# NUC1263AE register map
File version: 1.0
Registers are 32-bit, read-write, reset 0x0 unless marked. A register's access mark holds for its fields unless they carry their own. Offsets are from the block's base; [hi:lo] are bit positions; {n}, {i} and the like mark numbered series.

## CRC — CRC Register Map
Base 0x50018000
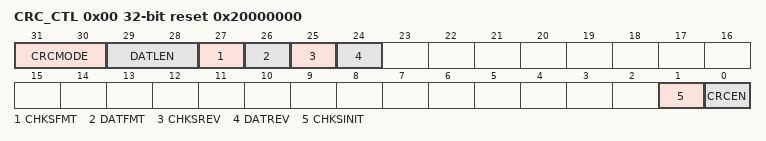
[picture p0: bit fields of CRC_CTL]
0x00 CRC_CTL reset 0x20000000 — CRC Control Register
  [31:30] CRCMODE — CRC Polynomial Mode. This field indicates the CRC operation polynomial mode.
    0=CRC-CCITT Polynomial mode; 1=CRC-8 Polynomial mode; 2=CRC-16 Polynomial mode; 3=CRC-32 Polynomial mode
  [29:28] DATLEN — CPU Write Data Length. This field indicates the valid write data length of DATA (CRC_DAT[31:0]). Note: When the write data length is 8-bit mode, the valid data in CRC_DAT register is only DATA[7:0] bits; if the write data length is 16-bit mode, the valid data in CRC_DAT register is only DATA[15:0].
    0=Data length is 8-bit mode; 1=Data length is 16-bit mode. Data length is 32-bit mode
  [27] CHKSFMT — Checksum 1's Complement Enable Bit. This bit is used to enable the 1's complement function for checksum result CHECKSUM (CRC_CHECKSUM[31:0]).
    0=1's complement for CRC CHECKSUM Disabled; 1=1's complement for CRC CHECKSUM Enabled
  [26] DATFMT — Write Data 1's Complement Enable Bit. This bit is used to enable the 1's complement function for write data value DATA (CRC_DATA[31:0]).
    0=1's complement for CRC DATA Disabled; 1=1's complement for CRC DATA Enabled
  [25] CHKSREV — Checksum Bit Order Reverse Enable Bit. This bit is used to enable the bit order reverse function for checksum result CHECKSUM (CRC_CHECKSUM[31:0]). Note: If the checksum result is 0xDD7B0F2E, the bit order reverse result for CRC checksum is 0x74F0DEBB.
    0=Bit order reverse for CRC CHECKSUM Disabled; 1=Bit order reverse for CRC CHECKSUM Enabled
  [24] DATREV — Write Data Bit Order Reverse Enable Bit. This bit is used to enable the bit order reverse function per byte for write data value DATA (CRC_DATA[31:0]). Note: If the write data is 0xAABBCCDD, the bit order reverse for CRC write data in is 0x55DD33BB.
    0=Bit order reversed for CRC DATA Disabled; 1=Bit order reversed for CRC DATA Enabled (per byte)
  [1] CHKSINIT — Checksum Initialization. Set this bit will auto reload SEED (CRC_SEED [31:0]) to CHECKSUM (CRC_CHECKSUM[31:0]) as CRC operation initial value. Note: This bit will be cleared automatically.
    0=No effect; 1=Reload SEED value to CHECKSUM as CRC operation initial value
  [0] CRCEN — CRC Generator Enable Bit. Set this bit 1 to enable CRC generator for CRC operation.
    0=No effect; 1=CRC generator is active
0x04 CRC_DAT — CRC Write Data Register
  [31:0] DATA — CRC Write Data Bits. User can write data directly by CPU mode or use PDMA function to write data to this field to perform CRC operation. Note: When the write data length is 8-bit mode, the valid data in CRC_DAT register is only DATA[7:0] bits; if the write data length is 16-bit mode, the valid data in CRC_DAT register is only DATA[15:0].
0x08 CRC_SEED reset 0xFFFFFFFF
  [31:0] SEED — CRC Seed Value. This field indicates the CRC seed value. Note 1: This SEED value will be loaded to checksum initial value CHECKSUM (CRC_CHECKSUM[31:0]) after set CHKSINIT (CRC_CTL[1]) to 1. Note 2: The valid bits of CRC_SEED[31:0] are correlated to CRCMODE (CRC_CTL[31:30]).
0x0C CRC_CHECKSUM ro reset 0xFFFFFFFF
  [31:0] CHECKSUM — CRC Checksum Results. This field indicates the CRC checksum result. Note: The valid bits of CRC_CHECKSUM[31:0] are correlated to CRCMODE (CRC_CTL[31:30]).

## DAC0 — DAC Register Map
Base 0x400F0000
Same registers: DAC1 0x400F0040, DAC2 0x400F0080, DAC3 0x400F00C0
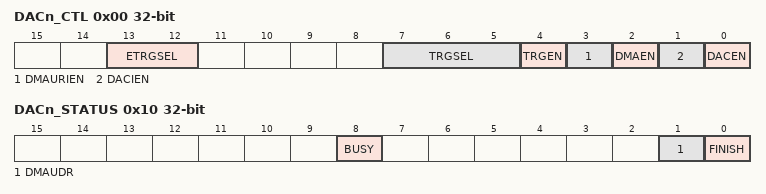
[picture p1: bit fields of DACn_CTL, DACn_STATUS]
0x00 DACn_CTL — DAC Control Register
  [13:12] ETRGSEL — External Pin Trigger Selection
    0=Low level trigger; 1=High level trigger; 2=Falling edge trigger; 3=Rising edge trigger
  [7:5] TRGSEL — Trigger Source Selection
    0=Software trigger; 1=External pin DAC_ST trigger; {v}=Timer {v-2} trigger (v=2..5)
  [4] TRGEN — Trigger Mode Enable Bit
    0=DAC event trigger mode Disabled; 1=DAC event trigger mode Enabled
  [3] DMAURIEN — DMA Under-run Interrupt Enable Bit
    0=DMA under-run interrupt Disabled; 1=DMA under-run interrupt Enabled
  [2] DMAEN — DMA Mode Enable Bit
    0=DMA mode Disabled; 1=DMA mode Enabled
  [1] DACIEN — DAC Interrupt Enable Bit
    0=DAC interrupt Disabled; 1=DAC interrupt Enabled
  [0] DACEN — DAC Enable Bit
    0=DAC Disabled; 1=DAC Enabled
0x04 DACn_SWTRG — DAC Software Trigger Control Register
  [0] SWTRG — Software Trigger. Note: User writes this bit to generate one shot pulse and this bit is cleared to 0 by hardware automatically; reading this bit will always get 0.
    0=Software trigger Disabled; 1=Software trigger Enabled
0x08 DACn_DAT — DAC Data Holding Register
  [7:0] DACDAT — DAC 8-bit Holding Data. These bits are written by user software which specifies 8-bit conversion data for DAC output.
0x0C DACn_DATOUT ro — DAC Data Output Register
  [7:0] DATOUT — DAC 8-bit Output Data. These bits are current digital data for DAC output conversion. It is loaded from DAC_DAT register and user cannot write it directly.
0x10 DACn_STATUS — DAC Status Register
  [8] BUSY ro — DAC Busy Flag (Read Only)
    0=DAC is ready for next conversion; 1=DAC is busy in conversion
  [1] DMAUDR — DMA Under-run Interrupt Flag. Note: User writes 1 to clear this bit.
    0=No DMA under-run error condition occurred; 1=DMA under-run error condition occurred
  [0] FINISH — DAC Conversion Complete Finish Flag. Note: This bit is set to 1 when conversion time counter counts to SETTLET. It is cleared to 0 when DAC starts a new conversion. User writes 1 to clear this bit to 0.
    0=DAC is in conversion state; 1=DAC conversion finish
0x14 DACn_TCTL — DAC Timing Control Register
  [9:0] SETTLET — DAC Output Settling Time. User software needs to write appropriate value to these bits to meet DAC conversion settling time base on PCLK (APB clock) speed. For example, DAC controller clock speed is 80 MHz and DAC conversion settling time is 1 us, SETTLETvalue must be greater than 0x50.
